# STM32H7P4 register map
File version: 2.0.0
CPU: CM7 r1p2, little endian, MPU, FPU, 4 interrupt priority bits
Registers are 32-bit, read-write, reset 0x0 unless marked. A register's access mark holds for its fields unless they carry their own. Offsets are from the block's base; [hi:lo] are bit positions; {n}, {i} and the like mark numbered series; 'fields as' and 'values as' point back to an identical list.

## PWR — PWR register block
Base 0x58024800
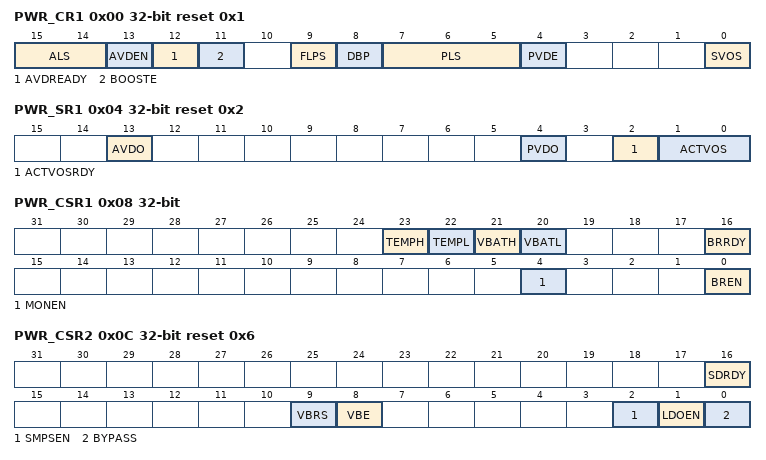
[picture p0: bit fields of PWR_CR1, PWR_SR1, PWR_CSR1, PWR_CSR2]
0x00 PWR_CR1 reset 0x1 — PWR control register 1
  [15:14] ALS — Analog voltage detector level selection
    {v}=AVD level {v+1} (v=0..3)
  [13] AVDEN — Peripheral voltage monitor on VDDA enable
    0=Peripheral voltage monitor on VDDA disabled; 1=Peripheral voltage monitor on VDDA enabled
  [12] AVDREADY — Analog voltage ready
    0=peripheral analog voltage VDDA not ready (default); 1=peripheral analog voltage VDDA ready
  [11] BOOSTE — Analog switch VBoost control
    0=booster disabled (default); 1=booster enabled if analog voltage ready (AVD_READY = 1)
  [9] FLPS — Flash low-power mode in Stop mode
    0=Flash memory remains in normal mode when device enters Stop (quick restart time); 1=Flash memory enters low-power mode when device enters Stop mode (low-power consumption)
  [8] DBP — Disable backup domain write protection
    0=Read and write access to RTC and RTC backup registers disabled and backup SRAM write access disabled; 1=Read and write access to RTC, RTC backup registers and backup SRAM enabled
  [7:5] PLS — Programmable voltage detector level selection
    {v}=VDD less than PVD level {v+1} (v=0..6); 7=PVD_IN less than VREFINT
  [4] PVDE — Programmable voltage detector enable
    0=Programmable voltage detector disabled; 1=Programmable voltage detector enabled
  [0] SVOS — System Stop mode voltage scaling selection
    0=SVOS low; 1=SVOS high (default)
0x04 PWR_SR1 ro reset 0x2 — PWR status register 1
  [13] AVDO — Analog voltage detector output on VDDA
    0=VDDA is equal or higher than the AVD threshold selected with the ALS[1:0] bits; 1=VDDA is lower than the AVD threshold selected with the ALS[1:0] bits
  [4] PVDO — Programmable voltage detect output
    0=VDD or PVD_IN voltage is equal or higher than the PVD threshold selected through the; 1=VDD or PVD_IN voltage is lower than the PVD threshold selected through the PLS[2:0]
  [2] ACTVOSRDY — Voltage levels ready bit for currently used ACTVOS
    0=Voltage level invalid, above or below current ACTVOS selected levels; 1=Voltage level valid, at current ACTVOS selected levels
  [1:0] ACTVOS — VOS currently applied for Vless thansub>COREless than/sub> voltage scaling selection
    1=VOS2; 2=VOS1; 3=VOS0
0x08 PWR_CSR1 — PWR control status register 1
  [23] TEMPH ro — Temperature level monitoring versus high threshold
    0=Temperature below high threshold level; 1=Temperature equal or above high threshold level
  [22] TEMPL ro — Temperature level monitoring versus low threshold
    0=Temperature above low threshold level; 1=Temperature equal or below low threshold level
  [21] VBATH ro — Vless thansub>BATless than/sub> level monitoring versus high threshold
    0=Vless thansub>BATless than/sub> level below high threshold level; 1=Vless thansub>BATless than/sub> level equal or above high threshold level
  [20] VBATL ro — Vless thansub>BATless than/sub> level monitoring versus low threshold
    0=Vless thansub>BATless than/sub> level above low threshold level; 1=Vless thansub>BATless than/sub> level equal or below low threshold level
  [16] BRRDY ro — Backup regulator ready
    0=Backup regulator not ready; 1=Backup regulator ready
  [4] MONEN — Vless thansub>BATless than/sub> and temperature monitoring enable
    0=Vless thansub>BATless than/sub> and temperature monitoring disabled; 1=Vless thansub>BATless than/sub> and temperature monitoring enabled
  [0] BREN — Backup regulator enable
    0=Backup regulator disabled; 1=Backup regulator enabled
0x0C PWR_CSR2 rw-once reset 0x6 — PWR control status register 2
  [16] SDRDY ro — Integrated SMPS step-down converter supply ready
    0=SMPS supply not ready; 1=SMPS supply ready
  [9] VBRS rw — VBAT charging resistor selection
    0=Charge VBAT through a 5 kohm resistor; 1=Charge VBAT through a 1
  [8] VBE rw — VBAT charging enable
    0=VBAT battery charging disabled; 1=VBAT battery charging enabled
  [2] SMPSEN ro — Integrated SMPS step-down converter enable (read only)
    0=SMPS step-down converter disabled; 1=SMPS step-down converter enabled
  [1] LDOEN ro — Integrated low drop-out regulator enable (read only)
    0=Low drop-out regulator disabled; 1=Low drop-out regulator enabled
  [0] BYPASS — Power management unit bypass
    0=Internal supply (LDO or SMPS); 1=External supply
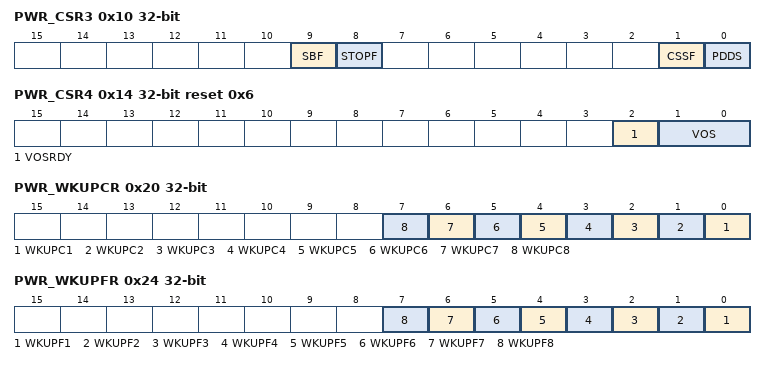
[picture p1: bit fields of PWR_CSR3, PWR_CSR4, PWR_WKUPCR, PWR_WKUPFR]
0x10 PWR_CSR3 — PWR CPU control status register 3
  [9] SBF ro — System Standby flag
    0=System has not been in Standby mode; 1=System has been in Standby mode
  [8] STOPF ro — Stop flag
    0=System has not been in Stop mode; 1=System has been in Stop mode
  [1] CSSF — Clear Standby and Stop flags (always read as 0)
    0=No effect; 1=flags (STOPF, SBF) are cleared
  [0] PDDS — Power-down Deepsleep.
    0=Stop mode when device enters Deepsleep; 1=Standby mode when device enters Deepsleep
0x14 PWR_CSR4 reset 0x6 — PWR control status register 4
  [2] VOSRDY ro — VOS ready bit for Vless thansub>COREless than/sub> voltage scaling output selection.
    0=Not ready, voltage level below VOS selected level; 1=Ready, voltage level at or above VOS selected level
  [1:0] VOS — Voltage scaling selection according to performance
    1=VOS2 (lowest power); 2=VOS1 (default); 3=VOS0 (highest frequency)
0x20 PWR_WKUPCR — PWR wakeup clear register
  [n-1] WKUPC{n} (n=1..8) — Clear wakeup pin flag for WKUP{n}
    0=No effect; 1=Writing 1 clears the WKUPF{n} flag (bit is cleared to 0 by hardware)
0x24 PWR_WKUPFR ro — PWR wakeup flag register
  [n-1] WKUPF{n} (n=1..8) — Wakeup pin WKUP{n} flag
    0=No wakeup event occurred; 1=A wakeup event was received from WKUP{n} pin
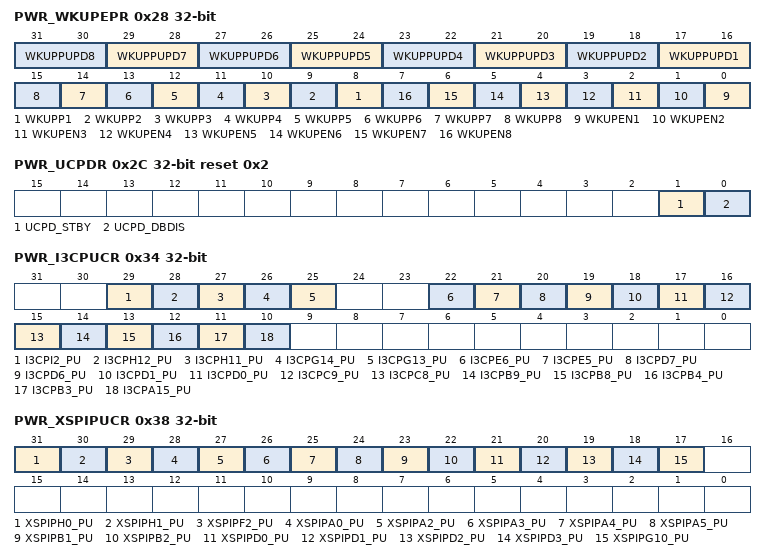
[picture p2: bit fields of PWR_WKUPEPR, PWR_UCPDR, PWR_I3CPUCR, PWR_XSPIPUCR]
0x28 PWR_WKUPEPR — PWR wakeup enable and polarity register
  [2n+15:2n+14] WKUPPUPD{n} (n=1..8) — Wakeup pin pull configuration for WKUPn
    0=No pull; 1=Pull-up; 2=Pull-down
  [n+7] WKUPP{n} (n=1..8) — Wakeup pin polarity bit for WKUPn
    0=Detection on high level (rising edge); 1=Detection on low level (falling edge)
  [n-1] WKUPEN{n} (n=1..8) — Enable wakeup pin WKUPn
    0=An event on WKUPn pin does not wakeup the system from Standby mode; 1=A rising or falling edge on WKUPn pin wakes-up the system from Standby mode
0x2C PWR_UCPDR reset 0x2 — PWR USB Type-C and power delivery register
  [1] UCPD_STBY — UCPDStandbymode
  [0] UCPD_DBDIS — UCPDdeadbatterydisable
    0=UCPDdeadbatterypull-downbehaviorenabledonUCPDx_CC1andUCPDx_CC2pins; 1=UCPDdeadbatterypull-downbehaviordisabledonUCPDx_CC1andUCPDx_CC2pins
0x30 PWR_APCR — PWR apply pull register
  [0] APC — Applypull-upandpull-downconfiguration
    0=TheI/Opull-upandconfigurationsdefinedin the I3C_PUCR and XSPI_PUCR/PDCRregistersarenotapplied. The I/Os are set to the default mode in Standby (analog/Hi-Z); 1=TheI/Opull-upandpull-downconfigurationsdefinedinthe I3C_PUCR and XSPI_PUCR/PDCRregistersareappliedinStandbymodeandafterwakeupuntilthis bit isreset to 0
0x34 PWR_I3CPUCR — PWR I3C pull-up control register
  [all] fields
    0=Pull-up is disabled in standby mode; 1=If PWR_APCR. APC = 1, pull-up is active in standby mode and after wakeup until PWR_APCR. APC is reset to 0.
  [29] I3CPI2_PU — Port PI2 I3C pull-up bit
  [28] I3CPH12_PU — Port PH12 I3C pull-up bit
  [27] I3CPH11_PU — Port PH11 I3C pull-up bit
  [26] I3CPG14_PU — Port PG14 I3C pull-up bit.
  [25] I3CPG13_PU — Port PG13 I3C pull-up bit
  [22] I3CPE6_PU — Port PE6 I3C pull-up bit
  [21] I3CPE5_PU — Port PE5 I3C pull-up bit
  [20] I3CPD7_PU — Port PD7 I3C pull-up bit
  [19] I3CPD6_PU — Port PD6 I3C pull-up bit
  [18] I3CPD1_PU — Port PD1 I3C pull-up bit
  [17] I3CPD0_PU — Port PD0 I3C pull-up bit
  [16] I3CPC9_PU — Port PC9 I3C pull-up bit
  [15] I3CPC8_PU — Port PC8 I3C pull-up bit
  [14] I3CPB9_PU — Port PB9 I3C pull-up bit
  [13] I3CPB8_PU — Port PB8 I3C pull-up bit
  [12] I3CPB4_PU — Port PB4 I3C pull-up bit
  [11] I3CPB3_PU — Port PB3 I3C pull-up bit
  [10] I3CPA15_PU — Port PA15 I3C pull-up bit
0x38 PWR_XSPIPUCR — PWR XSPI pull-up control register
  [all] fields
    values as the fields of PWR_I3CPUCR
  [31] XSPIPH0_PU — Port PH0 XSPI pull-up bit
  [30] XSPIPH1_PU — Port PH1 XSPI pull-up bit
  [29] XSPIPF2_PU — Port PF2 XSPI pull-up bit
  [28] XSPIPA0_PU — Port PA0 XSPI pull-up bit
  [29-n] XSPIPA{n}_PU (n=2..5) — Port PA{n} XSPI pull-up bit
  [23] XSPIPB1_PU — Port PB1 XSPI pull-up bit
  [22] XSPIPB2_PU — Port PB2 XSPI pull-up bit
  [21-n] XSPIPD{n}_PU (n=0..3) — Port PD{n} XSPI pull-up bit
  [17] XSPIPG10_PU — Port PG10 XSPI pull-up bit
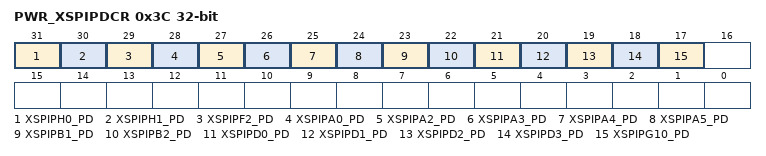
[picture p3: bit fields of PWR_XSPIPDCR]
0x3C PWR_XSPIPDCR — PWR XSPI pull-down control register
  [all] fields
    0=Pull-down is disabled in standby mode; 1=If PWR_APCR. APC = 1, pull-down is active in standby mode and after wakeup until PWR_APCR. APC is reset to 0.
  [31] XSPIPH0_PD — Port PH0 XSPI pull-down bit
  [30] XSPIPH1_PD — Port PH1 XSPI pull-down bit
  [29] XSPIPF2_PD — Port PF2 XSPI pull-down bit
  [28] XSPIPA0_PD — Port PA0 XSPI pull-down bit
  [29-n] XSPIPA{n}_PD (n=2..5) — Port PA{n} XSPI pull-down bit
  [23] XSPIPB1_PD — Port PB1 XSPI pull-down bit
  [22] XSPIPB2_PD — Port PB2 XSPI pull-down bit
  [21-n] XSPIPD{n}_PD (n=0..3) — Port PD{n} XSPI pull-down bit
  [17] XSPIPG10_PD — Port PG10 XSPI pull-down bit
